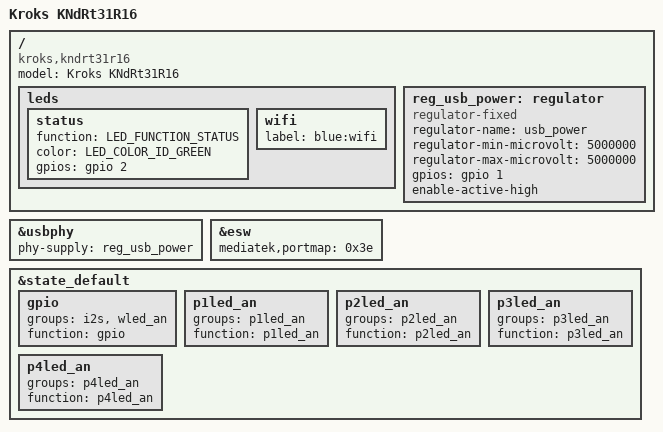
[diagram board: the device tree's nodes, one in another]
// SPDX-License-Identifier: GPL-2.0-or-later OR MIT

#include <dt-bindings/leds/common.h>

#include "mt7628an_kroks.dtsi"

/ {
	compatible = "kroks,kndrt31r16", "mediatek,mt7628an-soc";
	model = "Kroks KNdRt31R16";

	leds {
		status {
			function = LED_FUNCTION_STATUS;
			color = <LED_COLOR_ID_GREEN>;
			gpios = <&gpio 2 GPIO_ACTIVE_HIGH>;
		};

		wifi {
			label = "blue:wifi";
		};
	};

	reg_usb_power: regulator {
		compatible = "regulator-fixed";
		regulator-name = "usb_power";
		regulator-min-microvolt = <5000000>;
		regulator-max-microvolt = <5000000>;
		gpios = <&gpio 1 GPIO_ACTIVE_HIGH>;
		enable-active-high;
	};
};

&usbphy {
	phy-supply = <&reg_usb_power>;
};

&esw {
	mediatek,portmap = <0x3e>;
};

&state_default {
	gpio {
		groups = "i2s", "wled_an";
		function = "gpio";
	};

	p1led_an {
		groups = "p1led_an";
		function = "p1led_an";
	};

	p2led_an {
		groups = "p2led_an";
		function = "p2led_an";
	};

	p3led_an {
		groups = "p3led_an";
		function = "p3led_an";
	};

	p4led_an {
		groups = "p4led_an";
		function = "p4led_an";
	};
};
